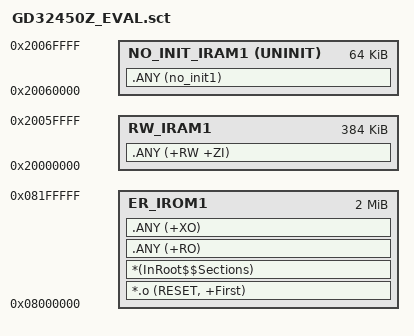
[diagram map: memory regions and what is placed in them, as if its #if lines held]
; *************************************************************
; *** Scatter-Loading Description File generated by uVision ***
; *************************************************************

LR_IROM1 0x08000000 0x00200000  {    ; load region size_region
  ER_IROM1 0x08000000 0x00200000  {  ; load address = execution address
   *.o (RESET, +First)
   *(InRoot$$Sections)
   .ANY (+RO)
   .ANY (+XO)
  }

  RW_IRAM1 0x20000000 0x00060000  {  ; RW data
   .ANY (+RW +ZI)
  }

  NO_INIT_IRAM1 0x20060000 UNINIT 0x00010000  {  ; RW data
#if   defined ( __CC_ARM )           ; Arm Compiler 4/5
   .ANY (no_init1)
#elif defined (__ARMCC_VERSION)      ;Arm Compiler 6
   .ANY (.bss.no.init1)
#endif
  }
  
}

